CM_ "AUTOGENERATED FILE, DO NOT EDIT"

CM_ "Imported file _comma.dbc starts here"

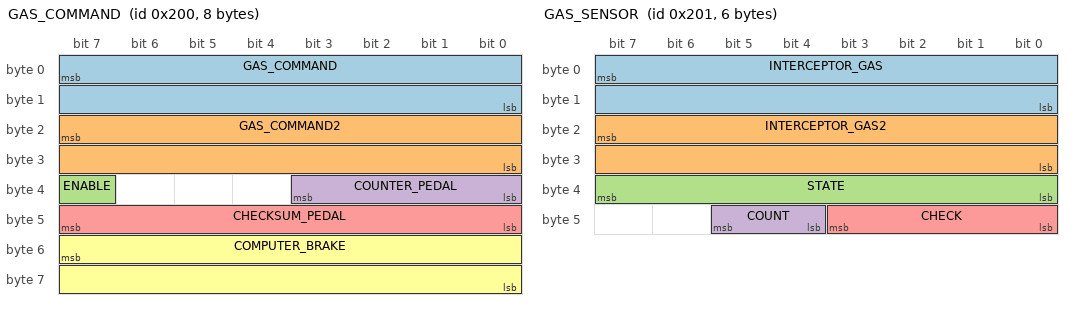
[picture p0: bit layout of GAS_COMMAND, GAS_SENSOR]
BO_ 512 GAS_COMMAND: 8 EON
 SG_ GAS_COMMAND : 7|16@0+ (0.253984064,-83.3) [0|1] "" INTERCEPTOR
 SG_ GAS_COMMAND2 : 23|16@0+ (0.126992032,-83.3) [0|1] "" INTERCEPTOR
 SG_ ENABLE : 39|1@0+ (1,0) [0|1] "" INTERCEPTOR
 SG_ COUNTER_PEDAL : 35|4@0+ (1,0) [0|15] "" INTERCEPTOR
 SG_ CHECKSUM_PEDAL : 47|8@0+ (1,0) [0|255] "" INTERCEPTOR
 SG_ COMPUTER_BRAKE : 55|16@0+ (0.005,1000) [0|65535] "" XXX

BO_ 513 GAS_SENSOR: 6 INTERCEPTOR
 SG_ INTERCEPTOR_GAS : 7|16@0+ (0.253984064,-83.3) [0|1] "" EON
 SG_ INTERCEPTOR_GAS2 : 23|16@0+ (0.126992032,-83.3) [0|1] "" EON
 SG_ STATE : 39|8@0+ (1,0) [0|255] "" EON
 SG_ COUNT : 45|2@0+ (1,0) [0|3] "" EON
 SG_ CHECK : 43|4@0+ (1,0) [0|3] "" EON

BO_ 0 RIEN: 6 RIEN

VAL_ 513 STATE 5 "FAULT_TIMEOUT" 4 "FAULT_STARTUP" 3 "FAULT_SCE" 2 "FAULT_SEND" 1 "FAULT_BAD_CHECKSUM" 0 "NO_FAULT" ;

CM_ "Imported file _honda_2017.dbc starts here"
VERSION ""

NS_ :

BU_: PCM MACC ABS EPS EON ADAS XXX

BO_ 228 STEERING_CONTROL: 5 ADAS
 SG_ STEER_TORQUE : 7|16@0+ (0.01,-1000) [0|65535] "" EPS
 SG_ STEER_CLIP : 16|16@0+ (1,0) [0|65535] "" EPS
 SG_ ANGLE_DES : 39|16@0+ (1,0) [0|65535] "deg" EPS

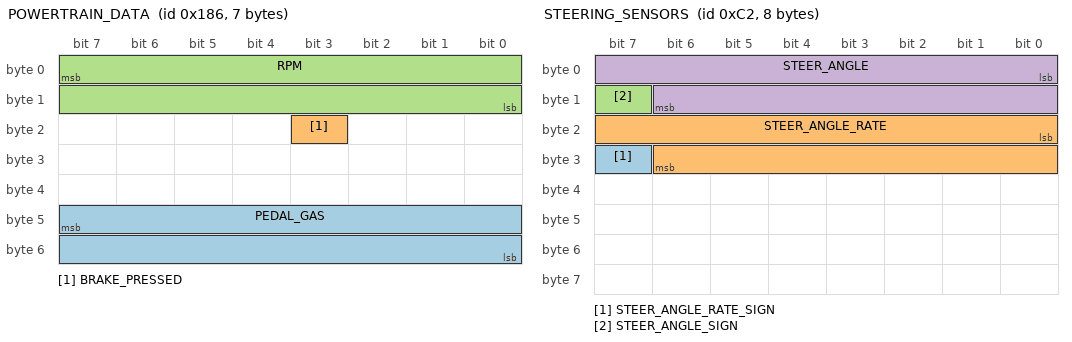
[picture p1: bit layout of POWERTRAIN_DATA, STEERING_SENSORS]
BO_ 390 POWERTRAIN_DATA: 7 PCM
 SG_ PEDAL_GAS : 47|16@0+ (1,0) [0|65535] "" XXX
 SG_ BRAKE_PRESSED : 19|1@0+ (1,0) [0|1] "" XXX
 SG_ RPM : 7|16@0+ (0.1,0) [0|65535] "rpm" XXX

BO_ 416 SPEEDS: 8 XXX
 SG_ SPEED1 : 17|15@1+ (0.01,0) [0|326.39] "km/h" XXX

BO_ 194 STEERING_SENSORS: 8 XXX
 SG_ STEER_ANGLE_RATE_SIGN : 31|1@1+ (1,0) [0|0] "" XXX
 SG_ STEER_ANGLE_RATE : 16|15@1+ (0.04375,0) [0|1433.6] "Grad/Sek" XXX
 SG_ STEER_ANGLE_SIGN : 15|1@1+ (1,0) [0|0] "" XXX
 SG_ STEER_ANGLE : 0|15@1+ (0.04375,0) [0|65535] "Grad" XXX

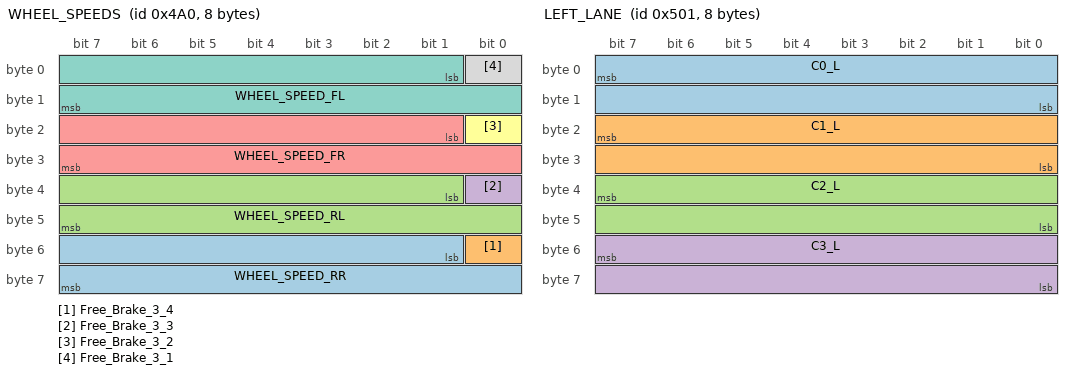
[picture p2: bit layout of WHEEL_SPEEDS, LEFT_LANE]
BO_ 1184 WHEEL_SPEEDS: 8 XXX
 SG_ WHEEL_SPEED_RR : 49|15@1+ (0.01,0) [0|326] "km/h" XXX
 SG_ Free_Brake_3_4 : 48|1@1+ (1,0) [0|0] "" XXX
 SG_ WHEEL_SPEED_RL : 33|15@1+ (0.01,0) [0|326] "km/h" XXX
 SG_ Free_Brake_3_3 : 32|1@1+ (1,0) [0|0] "" XXX
 SG_ WHEEL_SPEED_FR : 17|15@1+ (0.01,0) [0|326] "km/h" XXX
 SG_ Free_Brake_3_2 : 16|1@1+ (0.01,0) [0|325] "km/h" XXX
 SG_ WHEEL_SPEED_FL : 1|15@1+ (0.01,0) [0|326] "km/h" XXX
 SG_ Free_Brake_3_1 : 0|1@1+ (1,0) [0|0] "" XXX

BO_ 1281 LEFT_LANE: 8 XXX
 SG_ C0_L : 7|16@0+ (1,0) [0|65535] "" XXX
 SG_ C1_L : 23|16@0+ (1,0) [0|65535] "" XXX
 SG_ C2_L : 39|16@0+ (1,0) [0|65535] "" XXX
 SG_ C3_L : 55|16@0+ (1,0) [0|65535] "" XXX

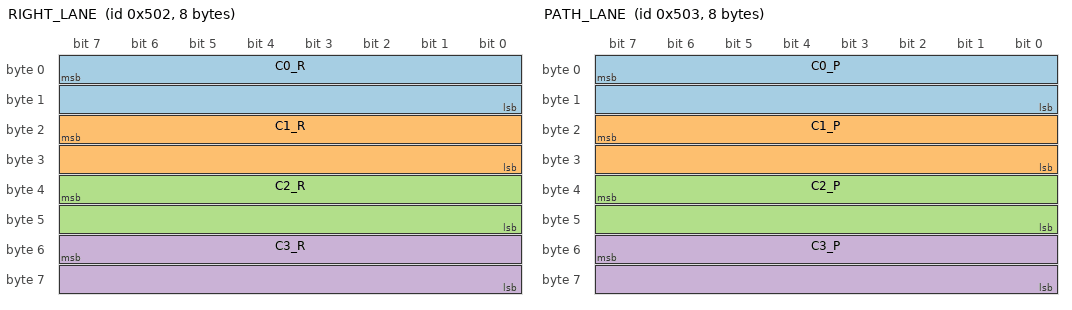
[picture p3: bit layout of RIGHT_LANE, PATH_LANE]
BO_ 1282 RIGHT_LANE: 8 XXX
 SG_ C0_R : 7|16@0+ (1,0) [0|65535] "" XXX
 SG_ C1_R : 23|16@0+ (1,0) [0|65535] "" XXX
 SG_ C2_R : 39|16@0+ (1,0) [0|65535] "" XXX
 SG_ C3_R : 55|16@0+ (1,0) [0|65535] "" XXX

BO_ 1283 PATH_LANE: 8 XXX
 SG_ C0_P : 7|16@0+ (1,0) [0|65535] "" XXX
 SG_ C1_P : 23|16@0+ (1,0) [0|65535] "" XXX
 SG_ C2_P : 39|16@0+ (1,0) [0|65535] "" XXX
 SG_ C3_P : 55|16@0+ (1,0) [0|65535] "" XXX

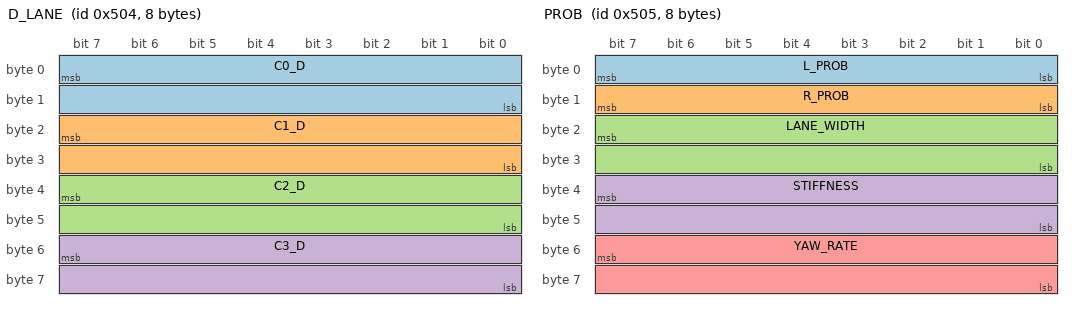
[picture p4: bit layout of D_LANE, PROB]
BO_ 1284 D_LANE: 8 XXX
 SG_ C0_D : 7|16@0+ (1,0) [0|65535] "" XXX
 SG_ C1_D : 23|16@0+ (1,0) [0|65535] "" XXX
 SG_ C2_D : 39|16@0+ (1,0) [0|65535] "" XXX
 SG_ C3_D : 55|16@0+ (1,0) [0|65535] "" XXX

BO_ 1285 PROB: 8 XXX
 SG_ L_PROB : 7|8@0+ (0.005,0) [0|256] "" XXX
 SG_ R_PROB : 15|8@0+ (0.005,0) [0|256] "" XXX
 SG_ LANE_WIDTH : 23|16@0+ (0.0001,0) [0|65535] "" XXX
 SG_ STIFFNESS : 39|16@0+ (0.0001,0) [0|65535] "" XXX
 SG_ YAW_RATE : 55|16@0+ (0.0005,-10) [0|65535] "" XXX

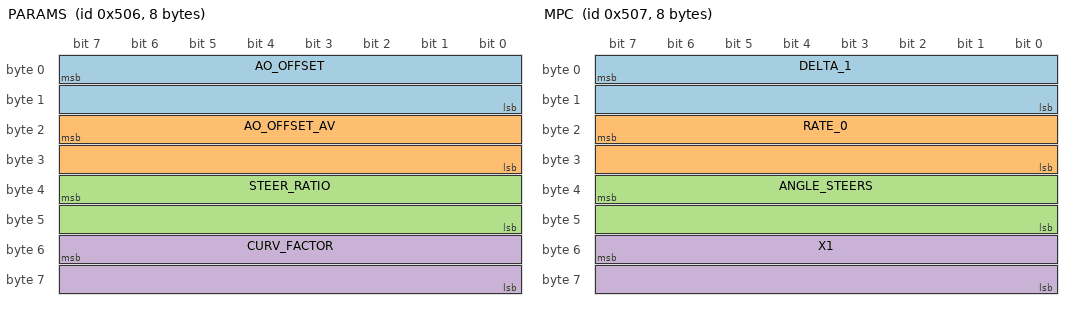
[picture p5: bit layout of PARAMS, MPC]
BO_ 1286 PARAMS: 8 XXX
 SG_ AO_OFFSET : 7|16@0+ (0.0005,-10) [0|65535] "" XXX
 SG_ AO_OFFSET_AV : 23|16@0+ (0.0005,-10) [0|65535] "" XXX
 SG_ STEER_RATIO : 39|16@0+ (0.0005,0) [0|65535] "" XXX
 SG_ CURV_FACTOR : 55|16@0+ (1,0) [0|65535] "" XXX

BO_ 1287 MPC: 8 XXX
 SG_ DELTA_1 : 7|16@0+ (1,0) [0|65535] "" XXX
 SG_ RATE_0 : 23|16@0+ (1,0) [0|65535] "" XXX
 SG_ ANGLE_STEERS : 39|16@0+ (1,0) [0|65535] "" XXX
 SG_ X1 : 55|16@0+ (0.001,0) [0|65535] "" XXX

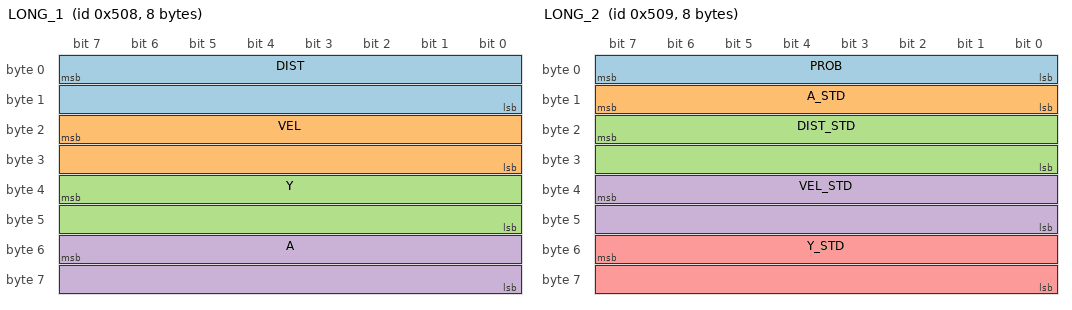
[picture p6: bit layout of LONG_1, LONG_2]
BO_ 1288 LONG_1: 8 XXX
 SG_ DIST : 7|16@0+ (1,0) [0|65535] "" XXX
 SG_ VEL : 23|16@0+ (1,0) [0|65535] "" XXX
 SG_ Y : 39|16@0+ (1,0) [0|65535] "" XXX
 SG_ A : 55|16@0+ (1,0) [0|65535] "" XXX

BO_ 1289 LONG_2: 8 XXX
 SG_ PROB : 7|8@0+ (1,0) [0|65535] "" XXX
 SG_ A_STD : 15|8@0+ (1,0) [0|65535] "" XXX
 SG_ DIST_STD : 23|16@0+ (1,0) [0|65535] "" XXX
 SG_ VEL_STD : 39|16@0+ (1,0) [0|65535] "" XXX
 SG_ Y_STD : 55|16@0+ (1,0) [0|65535] "" XXX

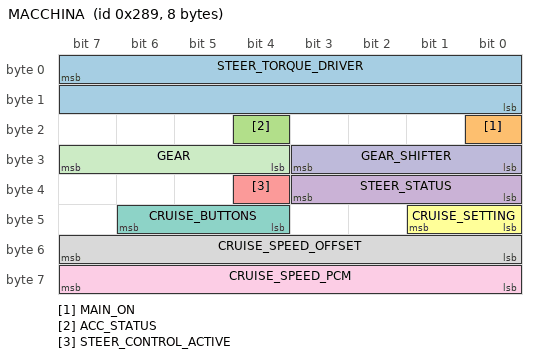
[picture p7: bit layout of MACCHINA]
BO_ 649 MACCHINA: 8 MACC
 SG_ STEER_TORQUE_DRIVER : 7|16@0- (1,0) [-31000|31000] "" EON
 SG_ MAIN_ON : 16|1@0+ (1,0) [0|1] "" EON
 SG_ ACC_STATUS : 20|1@0+ (1,0) [0|1] "" EON
 SG_ STEER_STATUS : 35|4@0+ (1,0) [0|15] "" EON
 SG_ STEER_CONTROL_ACTIVE : 36|1@0+ (1,0) [0|1] "" EON
 SG_ CRUISE_SETTING : 41|2@0+ (1,0) [0|3] "" EON
 SG_ CRUISE_BUTTONS : 46|3@0+ (1,0) [0|7] "" EON
 SG_ CRUISE_SPEED_OFFSET : 55|8@0- (0.1,0) [-128|127] "kmh" EON
 SG_ CRUISE_SPEED_PCM : 63|8@0+ (1,0) [0|255] "kmh" EON
 SG_ GEAR_SHIFTER : 24|4@1+ (1,0) [0|15] "" EON
 SG_ GEAR : 31|4@0+ (1,0) [0|15] "" EON

VAL_ 649 GEAR_SHIFTER 32 "L" 16 "S" 8 "D" 4 "N" 2 "R" 1 "P" ;
VAL_ 649 GEAR 7 "L" 10 "S" 4 "D" 3 "N" 2 "R" 1 "P" ;
VAL_ 649 CRUISE_BUTTONS 7 "tbd" 6 "tbd" 5 "tbd" 4 "accel_res" 3 "decel_set" 2 "cancel" 1 "main" 0 "none" ;
VAL_ 649 CRUISE_SETTING 3 "distance_adj" 2 "tbd" 1 "lkas_button" 0 "none" ;
